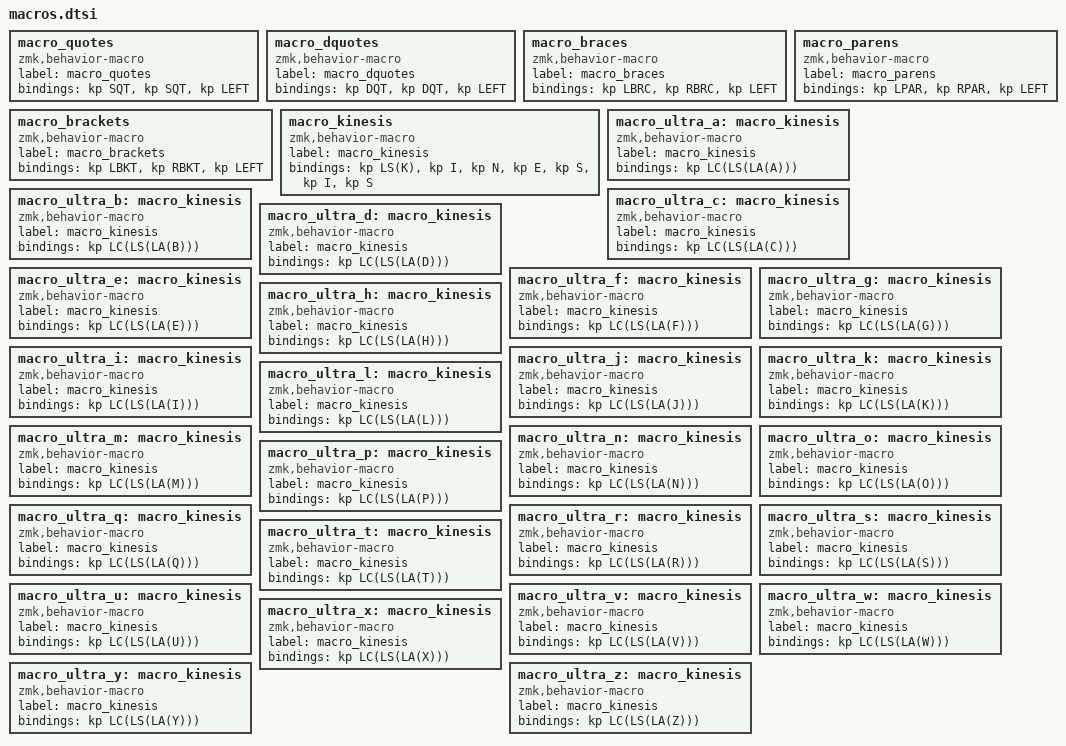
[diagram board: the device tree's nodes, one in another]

macro_quotes: macro_quotes{
compatible = "zmk,behavior-macro";
label = "macro_quotes";
#binding-cells = <0>;
bindings = <&kp SQT>, <&kp SQT>, <&kp LEFT>;
};
macro_dquotes: macro_dquotes{
compatible = "zmk,behavior-macro";
label = "macro_dquotes";
#binding-cells = <0>;
bindings = <&kp DQT>, <&kp DQT>, <&kp LEFT>;
};
macro_braces: macro_braces{
compatible = "zmk,behavior-macro";
label = "macro_braces";
#binding-cells = <0>;
bindings = <&kp LBRC>, <&kp RBRC>, <&kp LEFT>;
};
macro_parens: macro_parens{
compatible = "zmk,behavior-macro";
label = "macro_parens";
#binding-cells = <0>;
bindings = <&kp LPAR>, <&kp RPAR>, <&kp LEFT>;
};
macro_brackets: macro_brackets{
compatible = "zmk,behavior-macro";
label = "macro_brackets";
#binding-cells = <0>;
bindings = <&kp LBKT>, <&kp RBKT>, <&kp LEFT>;
};
macro_kinesis: macro_kinesis{
compatible = "zmk,behavior-macro";
label = "macro_kinesis";
#binding-cells = <0>;
bindings = <&kp LS(K)>, <&kp I>, <&kp N>, <&kp E>, <&kp S>, <&kp I>, <&kp S>;
};
macro_kinesis: macro_kinesis{
compatible = "zmk,behavior-macro";
label = "macro_kinesis";
#binding-cells = <0>;
bindings = <&kp LS(K)>, <&kp I>, <&kp N>, <&kp E>, <&kp S>, <&kp I>, <&kp S>;
};

macro_ultra_a: macro_kinesis{
compatible = "zmk,behavior-macro";
label = "macro_kinesis";
#binding-cells = <0>;
bindings = <&kp LC(LS(LA(A)))>;
};

macro_ultra_b: macro_kinesis{
compatible = "zmk,behavior-macro";
label = "macro_kinesis";
#binding-cells = <0>;
bindings = <&kp LC(LS(LA(B)))>;
};

macro_ultra_c: macro_kinesis{
compatible = "zmk,behavior-macro";
label = "macro_kinesis";
#binding-cells = <0>;
bindings = <&kp LC(LS(LA(C)))>;
};

macro_ultra_d: macro_kinesis{
compatible = "zmk,behavior-macro";
label = "macro_kinesis";
#binding-cells = <0>;
bindings = <&kp LC(LS(LA(D)))>;
};

macro_ultra_e: macro_kinesis{
compatible = "zmk,behavior-macro";
label = "macro_kinesis";
#binding-cells = <0>;
bindings = <&kp LC(LS(LA(E)))>;
};

macro_ultra_f: macro_kinesis{
compatible = "zmk,behavior-macro";
label = "macro_kinesis";
#binding-cells = <0>;
bindings = <&kp LC(LS(LA(F)))>;
};

macro_ultra_g: macro_kinesis{
compatible = "zmk,behavior-macro";
label = "macro_kinesis";
#binding-cells = <0>;
bindings = <&kp LC(LS(LA(G)))>;
};

macro_ultra_h: macro_kinesis{
compatible = "zmk,behavior-macro";
label = "macro_kinesis";
#binding-cells = <0>;
bindings = <&kp LC(LS(LA(H)))>;
};

macro_ultra_i: macro_kinesis{
compatible = "zmk,behavior-macro";
label = "macro_kinesis";
#binding-cells = <0>;
bindings = <&kp LC(LS(LA(I)))>;
};

macro_ultra_j: macro_kinesis{
compatible = "zmk,behavior-macro";
label = "macro_kinesis";
#binding-cells = <0>;
bindings = <&kp LC(LS(LA(J)))>;
};


macro_ultra_k: macro_kinesis{
compatible = "zmk,behavior-macro";
label = "macro_kinesis";
#binding-cells = <0>;
bindings = <&kp LC(LS(LA(K)))>;
};

macro_ultra_l: macro_kinesis{
compatible = "zmk,behavior-macro";
label = "macro_kinesis";
#binding-cells = <0>;
bindings = <&kp LC(LS(LA(L)))>;
};


macro_ultra_m: macro_kinesis{
compatible = "zmk,behavior-macro";
label = "macro_kinesis";
#binding-cells = <0>;
bindings = <&kp LC(LS(LA(M)))>;
};

macro_ultra_n: macro_kinesis{
compatible = "zmk,behavior-macro";
label = "macro_kinesis";
#binding-cells = <0>;
bindings = <&kp LC(LS(LA(N)))>;
};

macro_ultra_o: macro_kinesis{
compatible = "zmk,behavior-macro";
label = "macro_kinesis";
#binding-cells = <0>;
bindings = <&kp LC(LS(LA(O)))>;
};


macro_ultra_p: macro_kinesis{
compatible = "zmk,behavior-macro";
label = "macro_kinesis";
#binding-cells = <0>;
bindings = <&kp LC(LS(LA(P)))>;
};

macro_ultra_q: macro_kinesis{
compatible = "zmk,behavior-macro";
label = "macro_kinesis";
#binding-cells = <0>;
bindings = <&kp LC(LS(LA(Q)))>;
};

macro_ultra_r: macro_kinesis{
compatible = "zmk,behavior-macro";
label = "macro_kinesis";
#binding-cells = <0>;
bindings = <&kp LC(LS(LA(R)))>;
};

macro_ultra_s: macro_kinesis{
compatible = "zmk,behavior-macro";
label = "macro_kinesis";
#binding-cells = <0>;
bindings = <&kp LC(LS(LA(S)))>;
};

macro_ultra_t: macro_kinesis{
compatible = "zmk,behavior-macro";
label = "macro_kinesis";
#binding-cells = <0>;
bindings = <&kp LC(LS(LA(T)))>;
};

macro_ultra_u: macro_kinesis{
compatible = "zmk,behavior-macro";
label = "macro_kinesis";
#binding-cells = <0>;
bindings = <&kp LC(LS(LA(U)))>;
};

macro_ultra_v: macro_kinesis{
compatible = "zmk,behavior-macro";
label = "macro_kinesis";
#binding-cells = <0>;
bindings = <&kp LC(LS(LA(V)))>;
};

macro_ultra_w: macro_kinesis{
compatible = "zmk,behavior-macro";
label = "macro_kinesis";
#binding-cells = <0>;
bindings = <&kp LC(LS(LA(W)))>;
};

macro_ultra_x: macro_kinesis{
compatible = "zmk,behavior-macro";
label = "macro_kinesis";
#binding-cells = <0>;
bindings = <&kp LC(LS(LA(X)))>;
};

macro_ultra_y: macro_kinesis{
compatible = "zmk,behavior-macro";
label = "macro_kinesis";
#binding-cells = <0>;
bindings = <&kp LC(LS(LA(Y)))>;
};

macro_ultra_z: macro_kinesis{
compatible = "zmk,behavior-macro";
label = "macro_kinesis";
#binding-cells = <0>;
bindings = <&kp LC(LS(LA(Z)))>;
};
